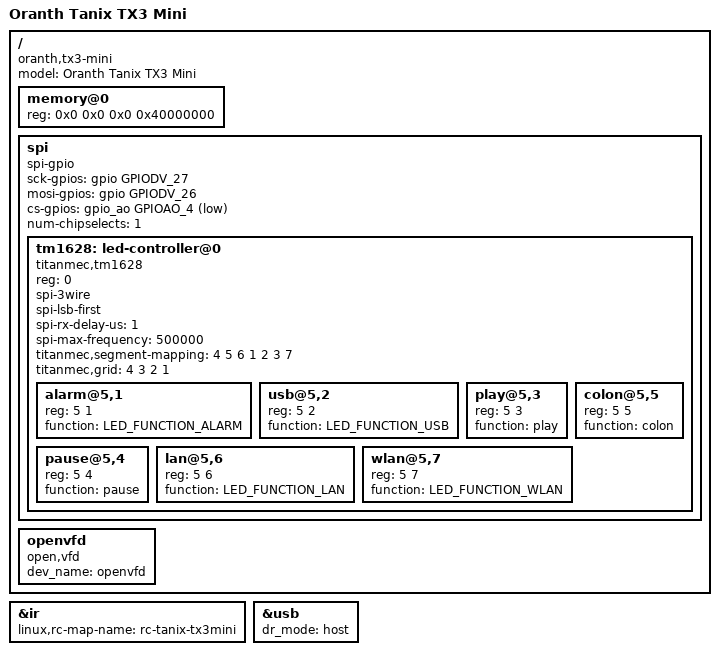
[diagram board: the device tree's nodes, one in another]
// SPDX-License-Identifier: (GPL-2.0+ OR MIT)
/*
 * Copyright (c) 2018 Martin Blumenstingl <martin.blumenstingl@googlemail.com>.
 * Based on meson-gxl-s905d-p231.dts:
 * - Copyright (c) 2016 Endless Computers, Inc.
 *   Author: Carlo Caione <carlo@endlessm.com>
 */

/dts-v1/;

#include "meson-gxl-s905x.dtsi"
#include "meson-gx-p23x-q20x.dtsi"
#include <dt-bindings/leds/common.h>

/ {
	compatible = "oranth,tx3-mini", "amlogic,s905w", "amlogic,meson-gxl";
	model = "Oranth Tanix TX3 Mini";

	memory@0 {
		device_type = "memory";
		reg = <0x0 0x0 0x0 0x40000000>; /* 1 GiB or 2 GiB */
	};

	spi {
		compatible = "spi-gpio";
		sck-gpios = <&gpio GPIODV_27  GPIO_ACTIVE_HIGH>;
		mosi-gpios = <&gpio GPIODV_26 GPIO_ACTIVE_HIGH>;
		cs-gpios = <&gpio_ao GPIOAO_4 GPIO_ACTIVE_LOW>;
		num-chipselects = <1>;
		#address-cells = <1>;
		#size-cells = <0>;

		tm1628: led-controller@0 {
			compatible = "titanmec,tm1628";
			reg = <0>;
			spi-3wire;
			spi-lsb-first;
			spi-rx-delay-us = <1>;
			spi-max-frequency = <500000>;
			#address-cells = <2>;
			#size-cells = <0>;

			titanmec,segment-mapping = /bits/ 8 <4 5 6 1 2 3 7>;
			titanmec,grid = /bits/ 8 <4 3 2 1>;

			alarm@5,1 {
				reg = <5 1>;
				function = LED_FUNCTION_ALARM;
			};

			usb@5,2 {
				reg = <5 2>;
				function = LED_FUNCTION_USB;
			};
			play@5,3 {
				reg = <5 3>;
				function = "play";
			};

			pause@5,4 {
				reg = <5 4>;
				function = "pause";
			};

			colon@5,5 {
				reg = <5 5>;
				function = "colon";
			};

			lan@5,6 {
				reg = <5 6>;
				function = LED_FUNCTION_LAN;
			};

			wlan@5,7 {
				reg = <5 7>;
				function = LED_FUNCTION_WLAN;
			};
		};
	};

	openvfd {
		compatible = "open,vfd";
		dev_name = "openvfd";
		status = "okay";
       };
};

&ir {
	linux,rc-map-name = "rc-tanix-tx3mini";
};

&usb {
	dr_mode = "host";
};
